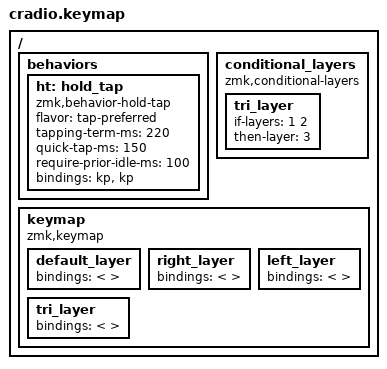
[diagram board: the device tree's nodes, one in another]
// Copyright (c) 2022 The ZMK Contributors
// SPDX-License-Identifier: MIT

#include <behaviors.dtsi>
#include <dt-bindings/zmk/keys.h>
#include <dt-bindings/zmk/bt.h>

// Home row mods macro
#define HRML(k1,k2,k3,k4) &ht LSHFT k1  &ht LALT k2  &ht LCTRL k3  &ht LGUI k4
#define HRMR(k1,k2,k3,k4) &ht RGUI k1  &ht RCTRL k2  &ht RALT k3  &ht RSHFT k4

/ {
    behaviors {
        ht: hold_tap {
            compatible = "zmk,behavior-hold-tap";
            #binding-cells = <2>;
            flavor = "tap-preferred";
            tapping-term-ms = <220>;
            quick-tap-ms = <150>;
            require-prior-idle-ms = <100>;
            bindings = <&kp>, <&kp>;
        };
    };

    conditional_layers {
        compatible = "zmk,conditional-layers";
        tri_layer {
            if-layers = <1 2>;
            then-layer = <3>;
        };
    };

    keymap {
        compatible = "zmk,keymap";
        default_layer {
            bindings = <
        //╭──────────┬──────────┬──────────┬──────────┬──────────╮   ╭──────────┬──────────┬──────────┬──────────┬──────────╮
        //│  Q       │  W       │  E       │  R       │  T       │   │  Y       │  U       │  I       │  O       │  P       │
        //├──────────┼──────────┼──────────┼──────────┼──────────┤   ├──────────┼──────────┼──────────┼──────────┼──────────┤
        //│  A       │  S       │  D       │  F       │  G       │   │  H       │  J       │  K       │  L       │ ' "      │
        //├──────────┼──────────┼──────────┼──────────┼──────────┤   ├──────────┼──────────┼──────────┼──────────┼──────────┤
        //│  Z       │  X       │  C       │  V       │  B       │   │  N       │  M       │          │          │   ?      │
        //╰──────────┴──────────┴──────────┼──────────┼──────────┤   ├──────────┼──────────┼──────────┴──────────┴──────────╯
        //                                 ╰──────────┴──────────╯   ╰──────────┴──────────╯
            >;
        };

        right_layer {
            bindings = <
        //╭──────────┬──────────┬──────────┬──────────┬──────────╮   ╭──────────┬──────────┬──────────┬──────────┬──────────╮
        //│ INSERT   │  1       │  2       │  3       │          │   │ HOME     │ PAGE DN  │ PAGE UP  │ END      │  :       │
        //├──────────┼──────────┼──────────┼──────────┼──────────┤   ├──────────┼──────────┼──────────┼──────────┼──────────┤
        //│ DELETE   │  4       │  5       │  6       │          │   │ LEFT     │ DOWN     │ UP       │ RIGHT    │  ;       │
        //├──────────┼──────────┼──────────┼──────────┼──────────┤   ├──────────┼──────────┼──────────┼──────────┼──────────┤
        //│ CAPS     │  7       │  8       │  9       │  0       │   │          │          │          │          │          │
        //╰──────────┴──────────┴──────────┼──────────┼──────────┤   ├──────────┼──────────┼──────────┴──────────┴──────────╯
        //                                 ╰──────────┴──────────╯   ╰──────────┴──────────╯
            >;
        };

        left_layer {
            bindings = <
        //╭──────────┬──────────┬──────────┬──────────┬──────────╮   ╭──────────┬──────────┬──────────┬──────────┬──────────╮
        //│          │  [       │  {       │  }       │          │   │  ^       │  (       │  )       │  ]       │  ~       │
        //├──────────┼──────────┼──────────┼──────────┼──────────┤   ├──────────┼──────────┼──────────┼──────────┼──────────┤
        //│  !       │  @       │  #       │  $       │  %       │   │  *       │  -       │  =       │  \       │  `       │
        //├──────────┼──────────┼──────────┼──────────┼──────────┤   ├──────────┼──────────┼──────────┼──────────┼──────────┤
        //│          │          │          │          │          │   │  &       │  _       │  +       │  │       │          │
        //╰──────────┴──────────┴──────────┼──────────┼──────────┤   ├──────────┼──────────┼──────────┴──────────┴──────────╯
        //                                 ╰──────────┴──────────╯   ╰──────────┴──────────╯
            >;
        };

        tri_layer {
            bindings = <
        //╭──────────┬──────────┬──────────┬──────────┬──────────╮   ╭──────────┬──────────┬──────────┬──────────┬──────────╮
        //│ RESET    │          │          │          │PROFILE 0 │   │          │          │          │          │  RESET   │
        //├──────────┼──────────┼──────────┼──────────┼──────────┤   ├──────────┼──────────┼──────────┼──────────┼──────────┤
        //│BOOTLOADER│          │          │          │PROFILE 1 │   │          │          │          │          │BOOTLOADER│
        //├──────────┼──────────┼──────────┼──────────┼──────────┤   ├──────────┼──────────┼──────────┼──────────┼──────────┤
        //│          │          │          │ CLEAR BT │PROFILE 2 │   │          │          │          │          │          │
        //╰──────────┴──────────┴──────────┼──────────┼──────────┤   ├──────────┼──────────┼──────────┴──────────┴──────────╯
        //                                 ╰──────────┴──────────╯   ╰──────────┴──────────╯
            >;
        };
    };
};
